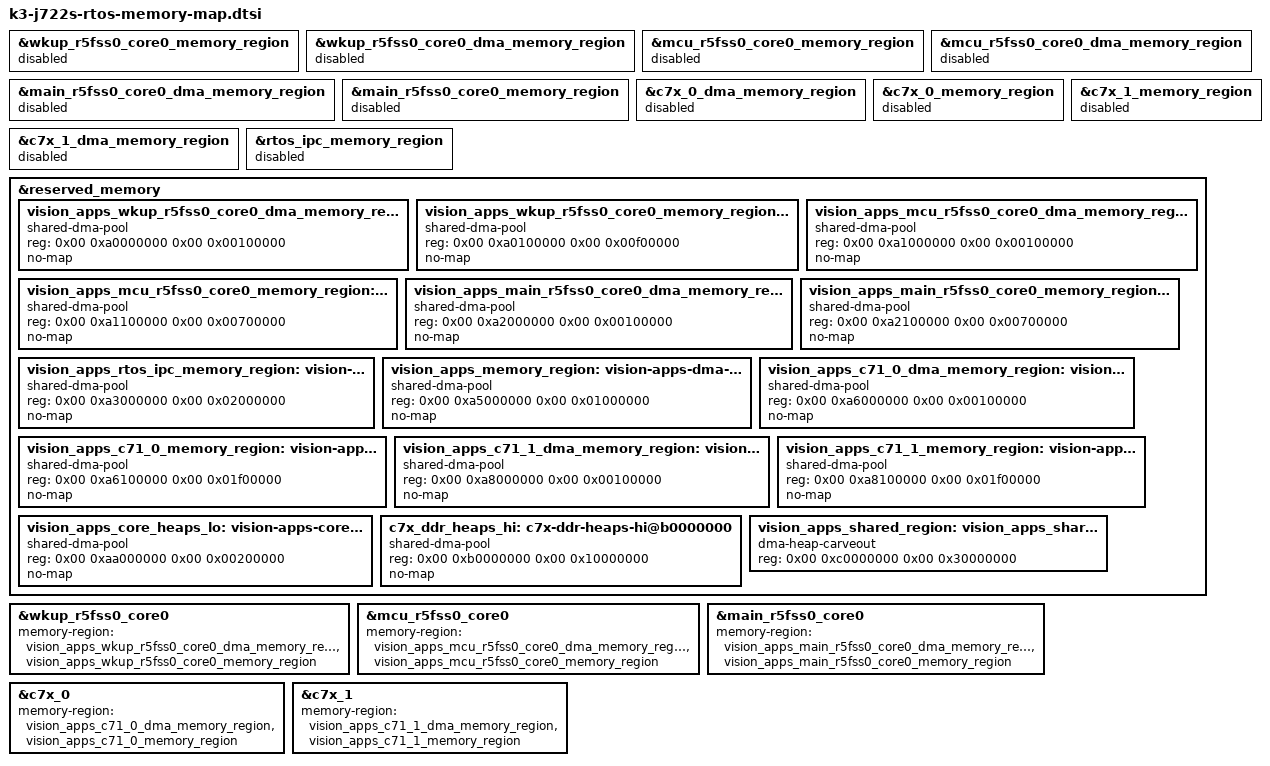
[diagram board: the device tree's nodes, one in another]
// SPDX-License-Identifier: GPL-2.0
/*
 * Vision-apps: device-tree overlay
 *
 * Copyright (C) 2019 Texas Instruments Incorporated - http://www.ti.com/
 */

#include <dt-bindings/soc/ti,sci_pm_domain.h>

/dts-v1/;
/plugin/;

&wkup_r5fss0_core0_memory_region {
	status = "disabled";
};

&wkup_r5fss0_core0_dma_memory_region {
	status = "disabled";
};

&mcu_r5fss0_core0_memory_region {
	status = "disabled";
};

&mcu_r5fss0_core0_dma_memory_region {
	status = "disabled";
};

&main_r5fss0_core0_dma_memory_region {
	status = "disabled";
};

&main_r5fss0_core0_memory_region {
	status = "disabled";
};

&c7x_0_dma_memory_region {
	status = "disabled";
};

&c7x_0_memory_region {
	status = "disabled";
};

&c7x_1_dma_memory_region {
	status = "disabled";
};

&c7x_1_memory_region {
	status = "disabled";
};

&rtos_ipc_memory_region {
	status = "disabled";
};

&reserved_memory {
	#address-cells = <2>;
	#size-cells = <2>;

	vision_apps_wkup_r5fss0_core0_dma_memory_region: vision-apps-r5f-dma-memory@a0000000 {
		compatible = "shared-dma-pool";
		reg = <0x00 0xa0000000 0x00 0x00100000>;
		no-map;
	};
	vision_apps_wkup_r5fss0_core0_memory_region: vision-apps-r5f-memory@a0100000 {
		compatible = "shared-dma-pool";
		reg = <0x00 0xa0100000 0x00 0x00f00000>;
		no-map;
	};
	vision_apps_mcu_r5fss0_core0_dma_memory_region: vision-apps-r5f-dma-memory@a1000000 {
		compatible = "shared-dma-pool";
		reg = <0x00 0xa1000000 0x00 0x00100000>;
		no-map;
	};
	vision_apps_mcu_r5fss0_core0_memory_region: vision-apps-r5f-memory@a1100000 {
		compatible = "shared-dma-pool";
		reg = <0x00 0xa1100000 0x00 0x00700000>;
		no-map;
	};
	vision_apps_main_r5fss0_core0_dma_memory_region: vision-apps-r5f-dma-memory@a2000000 {
		compatible = "shared-dma-pool";
		reg = <0x00 0xa2000000 0x00 0x00100000>;
		no-map;
	};
	vision_apps_main_r5fss0_core0_memory_region: vision-apps-r5f-memory@a2100000 {
		compatible = "shared-dma-pool";
		reg = <0x00 0xa2100000 0x00 0x00700000>;
		no-map;
	};
	vision_apps_rtos_ipc_memory_region: vision-apps-rtos-ipc-memory-region@a3000000 {
		compatible = "shared-dma-pool";
		reg = <0x00 0xa3000000 0x00 0x02000000>;
		no-map;
	};
	vision_apps_memory_region: vision-apps-dma-memory@a5000000 {
		compatible = "shared-dma-pool";
		reg = <0x00 0xa5000000 0x00 0x01000000>;
		no-map;
	};
	vision_apps_c71_0_dma_memory_region: vision-apps-c71-dma-memory@a6000000 {
		compatible = "shared-dma-pool";
		reg = <0x00 0xa6000000 0x00 0x00100000>;
		no-map;
	};
	vision_apps_c71_0_memory_region: vision-apps-c71_0-memory@a6100000 {
		compatible = "shared-dma-pool";
		reg = <0x00 0xa6100000 0x00 0x01f00000>;
		no-map;
	};
	vision_apps_c71_1_dma_memory_region: vision-apps-c71_1-dma-memory@a8000000 {
		compatible = "shared-dma-pool";
		reg = <0x00 0xa8000000 0x00 0x00100000>;
		no-map;
	};
	vision_apps_c71_1_memory_region: vision-apps-c71_1-memory@a8100000 {
		compatible = "shared-dma-pool";
		reg = <0x00 0xa8100000 0x00 0x01f00000>;
		no-map;
	};
	vision_apps_core_heaps_lo: vision-apps-core-heap-memory-lo@aa000000 {
		compatible = "shared-dma-pool";
		reg = <0x00 0xaa000000 0x00 0x00200000>;
		no-map;
	};
	c7x_ddr_heaps_hi: c7x-ddr-heaps-hi@b0000000 {
		compatible = "shared-dma-pool";
		reg = <0x00 0xb0000000 0x00 0x10000000>;
		no-map;
	};
	vision_apps_shared_region: vision_apps_shared-memories {
		compatible = "dma-heap-carveout";
		reg = <0x00 0xc0000000 0x00 0x30000000>;
	};
};

&wkup_r5fss0_core0 {
	memory-region = <&vision_apps_wkup_r5fss0_core0_dma_memory_region>,
			<&vision_apps_wkup_r5fss0_core0_memory_region>;
};

&mcu_r5fss0_core0 {
	memory-region = <&vision_apps_mcu_r5fss0_core0_dma_memory_region>,
			<&vision_apps_mcu_r5fss0_core0_memory_region>;
};

&main_r5fss0_core0 {
	memory-region = <&vision_apps_main_r5fss0_core0_dma_memory_region>,
			<&vision_apps_main_r5fss0_core0_memory_region>;
};

&c7x_0 {
	memory-region = <&vision_apps_c71_0_dma_memory_region>,
			<&vision_apps_c71_0_memory_region>;
};

&c7x_1 {
	memory-region = <&vision_apps_c71_1_dma_memory_region>,
			<&vision_apps_c71_1_memory_region>;
};
